# UFS0_IPS_TCLK_ERR_INJ_CFG register map
Vendor: Texas Instruments
Peripheral module from a debugger description file (folder J7ES).
Registers are 32-bit, access per field, reset 0x0 unless marked. A register's access mark holds for its fields unless they carry their own. Offsets are as the file gives them; lines under a group give offsets from that group; [hi:lo] are bit positions; {n}, {i} and the like mark numbered series; 'fields as' and 'values as' point back to an identical list; <NAME> marks a mode.

## UFS0_IPS_TCLK_ERR_INJ_CFG
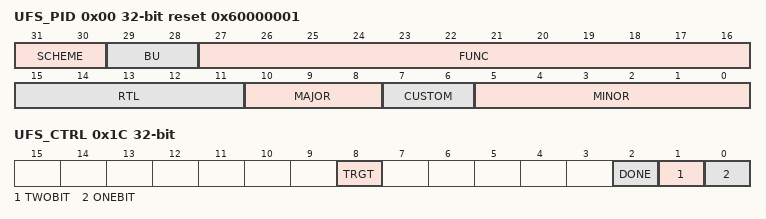
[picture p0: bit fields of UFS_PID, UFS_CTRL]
0x00 UFS_PID ro reset 0x60000001 — The Revision Register contains the major and minor revisions for the module.
  [31:30] SCHEME
  [29:28] BU — Business Unit: 2h = Processors
  [27:16] FUNC — Module ID
  [15:11] RTL — RTL Revision
  [10:8] MAJOR — Major Revision
  [7:6] CUSTOM
  [5:0] MINOR — Minor Revision
0x04 UFS_INFO ro reset 0x1 — The Info Register gives the configuration information of the module.
  [1:0] ENDPOINTS — Total number of Targets supported by this configuration.
0x08 UFS_SFT_RST — The Global Soft Reset Register clears all programmable registers and returns the injector to idle state.
  [3:0] KEY wo — Write Ah to issue a soft reset. All other written values are ignored. Always read as 0h.
0x10 UFS_BIT1 — The Bit 1 Mask Register defines the first bit to be flipped when injection is enabled.
  [15:0] BIT1 rw — First bit to be flipped on an error injection.
0x14 UFS_BIT2 — The Bit 2 Mask Register defines the second bit to be flipped if 2-bit injection is enabled.
  [15:0] BIT2 rw — Second bit to be flipped on an error injection if 2-bit injection is chosen.
0x18 UFS_TRGT — The Target Select Register selects which target to interact with.
  [0] TRGT rw — Select which target to interact with. Writes of a value higher than the number of targets supported by this configuration will have no effect.
0x1C UFS_CTRL — The Control Register controls the injection.
  [8] TRGT ro — Indicates which target is selected by theUFS_TRGT register.
  [2] DONE ro — Indicates that the target selected by theUFS_TRGT register has completed error injection. Thе UFS_STATUS register supersedes the armed bit.
  [1] TWOBIT rw — Write 1h to trigger a 2-bit error in target selected by theUFS_TRGT register. Write 0h to finish or cancel 2-bit injection. If both 1 and 2-bit injection are set, 2-bit injection will be performed.
  [0] ONEBIT rw — Write 1h to trigger a 1-bit error in target selected by theUFS_TRGT register. Write 0h to finish or cancel 1-bit injection.
0x20 UFS_STATUS ro — The Status Register controls the injection.
  [2] ARMED — Indicates that the target selected by theUFS_TRGT register is ARMED for error injection.
